# STM32F40x register map
File version: 1.5
Registers are 32-bit, read-write, reset 0x0 unless marked. A register's access mark holds for its fields unless they carry their own. Offsets are from the block's base; [hi:lo] are bit positions; {n}, {i} and the like mark numbered series.

## GPIOI（端口I） — 通用输入输出端口：引脚模式/输出/复用配置与读写 | General-purpose I/Os
Base 0x40022000
Same registers: GPIOC（端口C） 0x40020800, GPIOD（端口D） 0x40020C00, GPIOE（端口E） 0x40021000, GPIOF（端口F） 0x40021400, GPIOG（端口G） 0x40021800, GPIOH（端口H） 0x40021C00
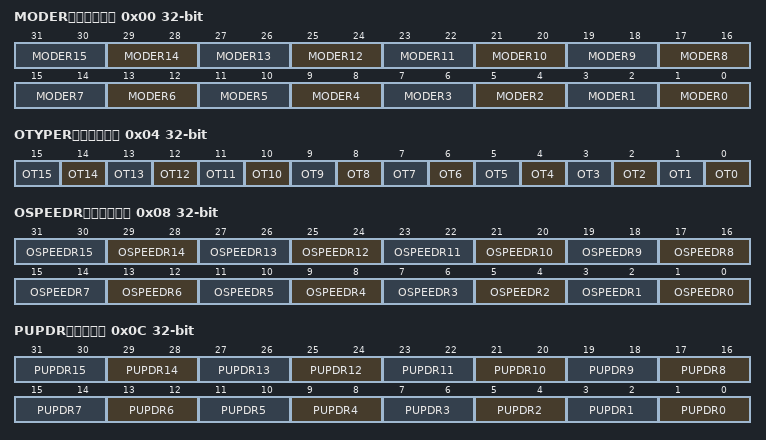
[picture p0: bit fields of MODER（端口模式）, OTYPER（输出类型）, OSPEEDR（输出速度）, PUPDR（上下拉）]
0x00 MODER（端口模式） — 端口模式：配置每引脚为 输入/输出/复用功能/模拟 | GPIO port mode register
  [2n+1:2n] MODER{n} (n=0..15) — Port x configuration bits (y = 0..15)
0x04 OTYPER（输出类型） — 输出类型：推挽 或 开漏 | GPIO port output type register
  [n] OT{n} (n=0..15) — Port x configuration bits (y = 0..15)
0x08 OSPEEDR（输出速度） — 输出速度：引脚翻转速率（低/中/高/超高速） | GPIO port output speed register
  [2n+1:2n] OSPEEDR{n} (n=0..15) — Port x configuration bits (y = 0..15)
0x0C PUPDR（上下拉） — 上拉/下拉：配置引脚上拉、下拉或浮空 | GPIO port pull-up/pull-down register
  [2n+1:2n] PUPDR{n} (n=0..15) — Port x configuration bits (y = 0..15)
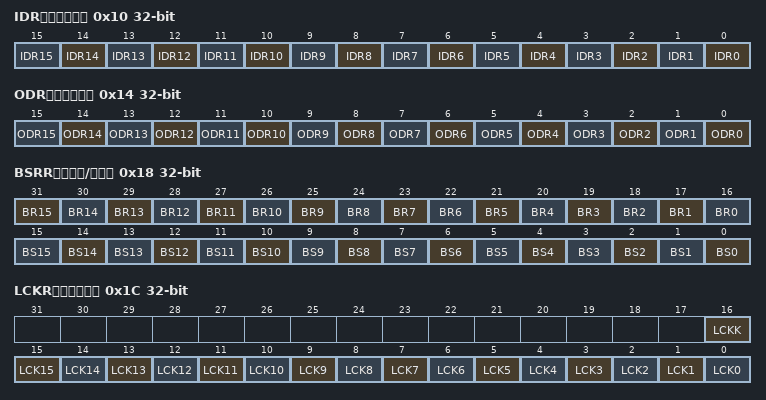
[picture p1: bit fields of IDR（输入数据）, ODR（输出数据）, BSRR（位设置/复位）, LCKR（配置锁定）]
0x10 IDR（输入数据） ro — 输入数据：读取各引脚当前电平（只读） | GPIO port input data register
  [n] IDR{n} (n=0..15) — Port input data (y = 0..15)
0x14 ODR（输出数据） — 输出数据：整个端口的输出值（改单脚建议用 BSRR） | GPIO port output data register
  [n] ODR{n} (n=0..15) — Port output data (y = 0..15)
0x18 BSRR（位设置/复位） wo — 位设置/复位：原子置位或清零某引脚，推荐用于输出驱动 | GPIO port bit set/reset register
  [n+16] BR{n} (n=1..15) — Port x reset bit y (y = 0..15)
  [16] BR0 — Port x set bit y (y= 0..15)
  [n] BS{n} (n=0..15) — Port x set bit y (y= 0..15)
0x1C LCKR（配置锁定） — 配置锁定：锁定引脚配置，防止被意外改写 | GPIO port configuration lock register
  [16] LCKK — Port x lock bit y (y= 0..15)
  [n] LCK{n} (n=0..15) — Port x lock bit y (y= 0..15)
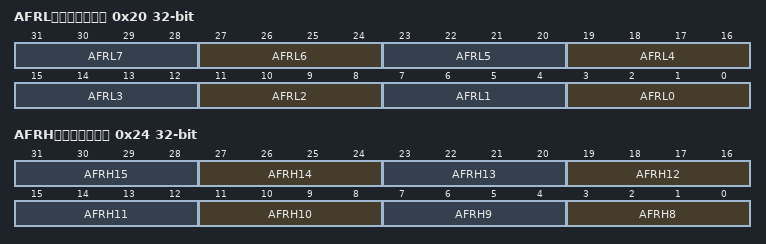
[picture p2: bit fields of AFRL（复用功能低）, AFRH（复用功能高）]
0x20 AFRL（复用功能低） — 引脚 0~7 的复用功能(AF0~AF15)选择 | GPIO alternate function low register
  [4n+3:4n] AFRL{n} (n=0..7) — Alternate function selection for port x bit y (y = 0..7)
0x24 AFRH（复用功能高） — 引脚 8~15 的复用功能(AF0~AF15)选择 | GPIO alternate function high register
  [4n-29:4n-32] AFRH{n} (n=8..15) — Alternate function selection for port x bit y (y = 8..15)

## GPIOB（端口B） — 通用输入输出端口：引脚模式/输出/复用配置与读写 | General-purpose I/Os
Base 0x40020400
Registers as GPIOI（端口I）; these are added or differ:
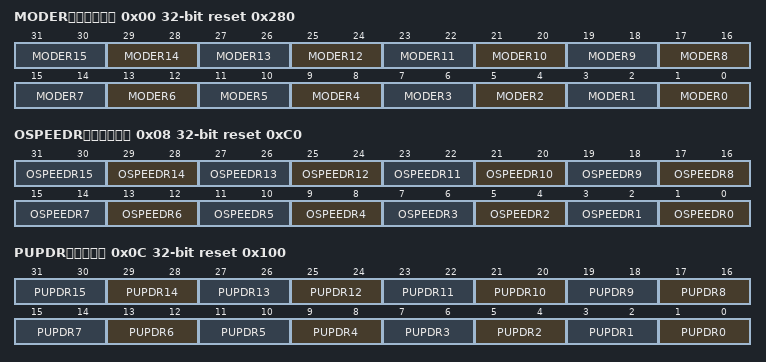
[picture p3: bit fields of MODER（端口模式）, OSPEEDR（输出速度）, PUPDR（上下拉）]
0x00 MODER（端口模式） reset 0x280 — 端口模式：配置每引脚为 输入/输出/复用功能/模拟 | GPIO port mode register
  [2n+1:2n] MODER{n} (n=0..15) — Port x configuration bits (y = 0..15)
0x08 OSPEEDR（输出速度） reset 0xC0 — 输出速度：引脚翻转速率（低/中/高/超高速） | GPIO port output speed register
  [2n+1:2n] OSPEEDR{n} (n=0..15) — Port x configuration bits (y = 0..15)
0x0C PUPDR（上下拉） reset 0x100 — 上拉/下拉：配置引脚上拉、下拉或浮空 | GPIO port pull-up/pull-down register
  [2n+1:2n] PUPDR{n} (n=0..15) — Port x configuration bits (y = 0..15)

## GPIOA（端口A） — 通用输入输出端口：引脚模式/输出/复用配置与读写 | General-purpose I/Os
Base 0x40020000
Registers as GPIOI（端口I）; these are added or differ:
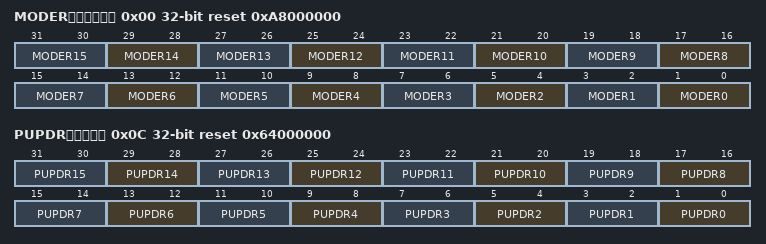
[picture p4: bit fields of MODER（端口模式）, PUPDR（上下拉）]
0x00 MODER（端口模式） reset 0xA8000000 — 端口模式：配置每引脚为 输入/输出/复用功能/模拟 | GPIO port mode register
  [2n+1:2n] MODER{n} (n=0..15) — Port x configuration bits (y = 0..15)
0x0C PUPDR（上下拉） reset 0x64000000 — 上拉/下拉：配置引脚上拉、下拉或浮空 | GPIO port pull-up/pull-down register
  [2n+1:2n] PUPDR{n} (n=0..15) — Port x configuration bits (y = 0..15)

## SYSCFG（系统配置） — 系统配置：存储器重映射/外部中断源选择 | System configuration controller
Base 0x40013800
0x00 MEMRM（内存重映射） — 内存重映射：ITCM/DTCM/外部存储器映射 | memory remap register
  [1:0] MEM_MODE
0x04 PMC（电源管理） — 电源管理：I/O 补偿单元等 | peripheral mode configuration register
  [23] MII_RMII_SEL — Ethernet PHY interface selection
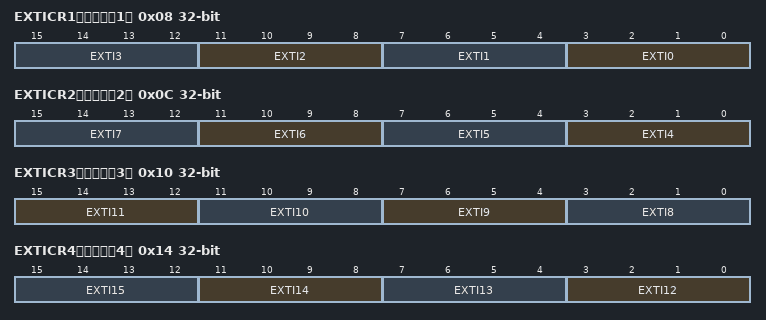
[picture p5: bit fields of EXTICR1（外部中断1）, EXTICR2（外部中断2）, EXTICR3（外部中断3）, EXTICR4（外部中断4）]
0x08 EXTICR1（外部中断1） — EXTI 线 0~3 的端口源选择 | external interrupt configuration register 1
  [4n+3:4n] EXTI{n} (n=0..3) — EXTI x configuration (x = 0 to 3)
0x0C EXTICR2（外部中断2） — EXTI 线 4~7 的端口源选择 | external interrupt configuration register 2
  [4n-13:4n-16] EXTI{n} (n=4..7) — EXTI x configuration (x = 4 to 7)
0x10 EXTICR3（外部中断3） — EXTI 线 8~11 的端口源选择 | external interrupt configuration register 3
  [15:12] EXTI11 — EXTI x configuration (x = 8 to 11)
  [11:8] EXTI10
  [7:4] EXTI9 — EXTI x configuration (x = 8 to 11)
  [3:0] EXTI8 — EXTI x configuration (x = 8 to 11)
0x14 EXTICR4（外部中断4） — EXTI 线 12~15 的端口源选择 | external interrupt configuration register 4
  [4n-45:4n-48] EXTI{n} (n=12..15) — EXTI x configuration (x = 12 to 15)
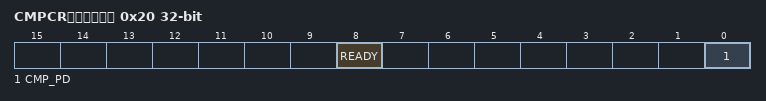
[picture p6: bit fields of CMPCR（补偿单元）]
0x20 CMPCR（补偿单元） ro — I/O 补偿单元状态 | Compensation cell control register
  [8] READY
  [0] CMP_PD — Compensation cell power-down
